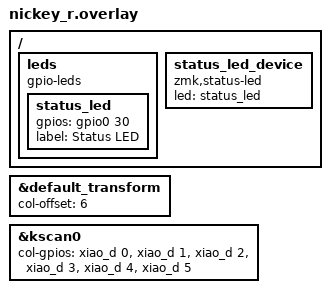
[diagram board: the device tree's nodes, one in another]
#include "nickey.dtsi"
#include <input/processors.dtsi>
#include <zephyr/dt-bindings/input/input-event-codes.h>

&default_transform {
    col-offset = <6>;
};

&kscan0 {
        col-gpios
            = <&xiao_d 0 GPIO_ACTIVE_HIGH>
            , <&xiao_d 1 GPIO_ACTIVE_HIGH>
            , <&xiao_d 2 GPIO_ACTIVE_HIGH>
            , <&xiao_d 3 GPIO_ACTIVE_HIGH>
            , <&xiao_d 4 GPIO_ACTIVE_HIGH>
            , <&xiao_d 5 GPIO_ACTIVE_HIGH>
            ;
};

/ {
    // Existing keyboard config...

    // Add a LED node here if not already defined by the board
    leds {
        compatible = "gpio-leds";
        status_led: status_led {
            gpios = <&gpio0 30 GPIO_ACTIVE_HIGH>; // Replace X and Y with your GPIO pin
            label = "Status LED";
        };
    };
    
    status_led_device: status_led_device {
        compatible = "zmk,status-led";
        led = <&status_led>;
    };
};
